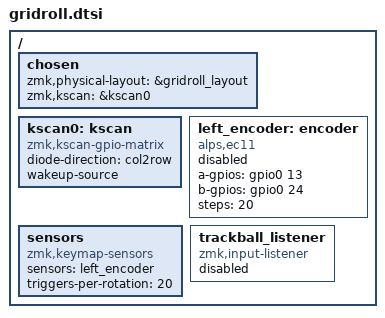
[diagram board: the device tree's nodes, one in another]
// SPDX-License-Identifier: MIT
#include "gridroll-layouts.dtsi"
/ {
    chosen { zmk,physical-layout = &gridroll_layout; zmk,kscan = &kscan0; };
    kscan0: kscan {
        compatible = "zmk,kscan-gpio-matrix";
        diode-direction = "col2row";
        wakeup-source;
    };
    left_encoder: encoder {
        compatible = "alps,ec11";
        a-gpios = <&gpio0 13 (GPIO_ACTIVE_HIGH | GPIO_PULL_UP)>;
        b-gpios = <&gpio0 24 (GPIO_ACTIVE_HIGH | GPIO_PULL_UP)>;
        steps = <20>;
        status = "disabled";
    };
    sensors: sensors {
        compatible = "zmk,keymap-sensors";
        sensors = <&left_encoder>;
        triggers-per-rotation = <20>;
    };
    trackball_listener: trackball_listener {
        compatible = "zmk,input-listener";
        status = "disabled";
    };
};
